# RL6845_IP_SVD register map
Vendor: Realtek
Registers are 32-bit, read-write, reset 0x0 unless marked. A register's access mark holds for its fields unless they carry their own. Offsets are from the block's base; [hi:lo] are bit positions.

## KSCAN_REG
Base 0x41013000
0x00 KS_CLK_DIV — clock division register
  [11:0] ks_clk_div — scan clock = bus clock/(keyscan_clk_div+1)
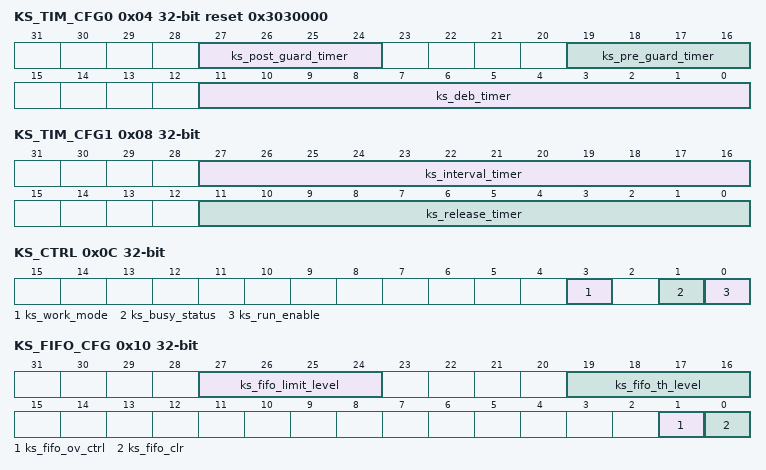
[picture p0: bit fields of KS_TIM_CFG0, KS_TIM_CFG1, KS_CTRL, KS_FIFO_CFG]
0x04 KS_TIM_CFG0 reset 0x3030000 — Key-Scan configure register 0
  [27:24] ks_post_guard_timer — Post guard time for key column, post guard time = scan_clk * reg_col_gt_post_sel
  [19:16] ks_pre_guard_timer — Pre guard time for key column, pre guard time = scan_clk * reg_col_gt_pre_sel
  [11:0] ks_deb_timer — Debounce counter n*scan_clk
0x08 KS_TIM_CFG1 — Key-Scan configure register 1
  [27:16] ks_interval_timer — Scan interval counter n*scan_clk
  [11:0] ks_release_timer — Release detect counter n*scan_clk
0x0C KS_CTRL access per field — Key-Scan control register
  [3] ks_work_mode rw — Work mode *0x1: Event Trigger Mode *0x0: Regular Scan Mode
  [1] ks_busy_status ro — FSM busy status
  [0] ks_run_enable rw — Enable internal Key-Scan scan clock. The Key-Scan clock enable must be after Key-Scan configuration is done. *0x1: Key-Scan clock enabled (HW FSM starts to run). *0x0: Key-Scan clock disabled (HW FSM stops).
0x10 KS_FIFO_CFG access per field — FIFO configuration register
  [27:24] ks_fifo_limit_level rw — Limit the max allowable key number be pressed at a time 0x0: no limit 0x1: only one scan data is allowable in each key scan ... 0x6: Max 6 scan data is allowable in each key scan 0x7 ~ 0xf: DO NOT USE
  [19:16] ks_fifo_th_level rw — FIFO threshold setup
  [1] ks_fifo_ov_ctrl rw — FIFO overflow control 0x0: rejects the new scan data when FIFO is full 0x1: discard the oldest scan data when FIFO is full
  [0] ks_fifo_clr wo — Write 1to clear FIFO data
0x14 KS_COL_CFG — column selection register
  [7:0] ks_col_sel — The control register to define which column is used. *0x0: No key column selected *0x1: Key column 0 selected *0x2: Key column 1 selected *0x3: Key column 0 and column 1 selected *0x4: Key column 2 selected *...
0x18 KS_ROW_CFG — row selection register
  [7:0] ks_row_sel — The control register to define which row is used. *0x0: No key row selected *0x1: Key row 0 selected *0x2: Key row 1 selected *0x3: Key row 0 and row 1 selected *0x4: Key row 2 selected *...
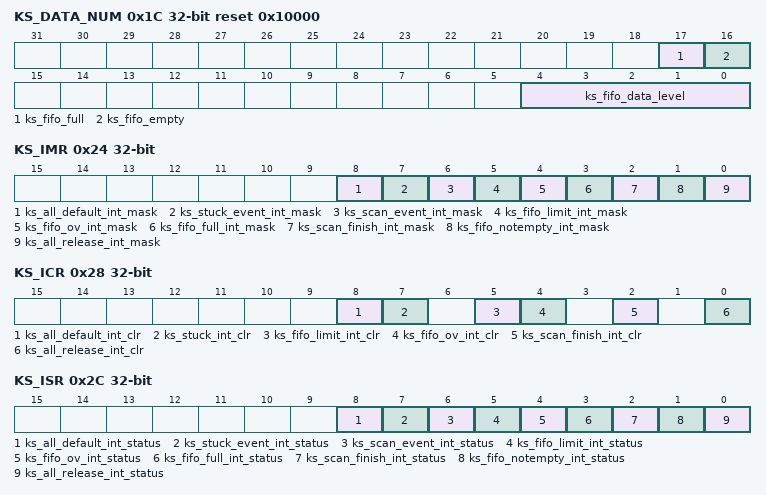
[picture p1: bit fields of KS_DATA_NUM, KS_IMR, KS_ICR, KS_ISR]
0x1C KS_DATA_NUM ro reset 0x10000 — FIFO status
  [17] ks_fifo_full — FIFO full status
  [16] ks_fifo_empty — FIFO empty status
  [4:0] ks_fifo_data_level — Number of entry in FIFO
0x20 KS_DATA ro — Key-Scan data register
  [11:0] ks_data — When reading this register, these bits return the value in the Event FIFO. *Bit[11:8]: press or release event **0x0: release event **0x1: press event *Bit[7:4]: row index *Bit[3:0]: column index
0x24 KS_IMR — interrupt mask register
  [8] ks_all_default_int_mask — 0x0: Mask all default interrupt
  [7] ks_stuck_event_int_mask — 0x0: Mask stuck event interrupt
  [6] ks_scan_event_int_mask — 0x0: Mask scan event interrupt
  [5] ks_fifo_limit_int_mask — 0x0: Mask FIFO limit interrupt
  [4] ks_fifo_ov_int_mask — 0x0: Mask FIFO overflow interrupt
  [3] ks_fifo_full_int_mask — 0x0: Mask FIFO full interrupt
  [2] ks_scan_finish_int_mask — 0x0: Mask scan finish interrupt
  [1] ks_fifo_notempty_int_mask — 0x0: Mask FIFO nonempty interrupt
  [0] ks_all_release_int_mask — 0x0: Mask All Release interrupt
0x28 KS_ICR wo — interrupt clear register
  [8] ks_all_default_int_clr — Clear All Default interrupt flag Write '1' to clear
  [7] ks_stuck_int_clr — Clear Stuck interrupt flag Write '1' to clear
  [5] ks_fifo_limit_int_clr — Clear FIFO limit interrupt flag Write '1' to clear
  [4] ks_fifo_ov_int_clr — Clear FIFO overflow interrupt flag Write '1' to clear
  [2] ks_scan_finish_int_clr — Clear scan finish interrupt flag Write '1' to clear
  [0] ks_all_release_int_clr — Clear all release interrupt flag Write '1' to clear
0x2C KS_ISR ro — interrupt status register
  [8] ks_all_default_int_status — Masked All Default interrupt status, means row status equal to ks_row_default_status
  [7] ks_stuck_event_int_status — Masked Stuck event interrupt status
  [6] ks_scan_event_int_status — Masked Scan event interrupt status
  [5] ks_fifo_limit_int_status — Masked FIFO limit interrupt status
  [4] ks_fifo_ov_int_status — Masked FIFO overflow interrupt status
  [3] ks_fifo_full_int_status — Masked FIFO full interrupt status
  [2] ks_scan_finish_int_status — Masked Scan finish interrupt status
  [1] ks_fifo_notempty_int_status — Masked FIFO nonempty interrupt status
  [0] ks_all_release_int_status — Masked All release interrupt status
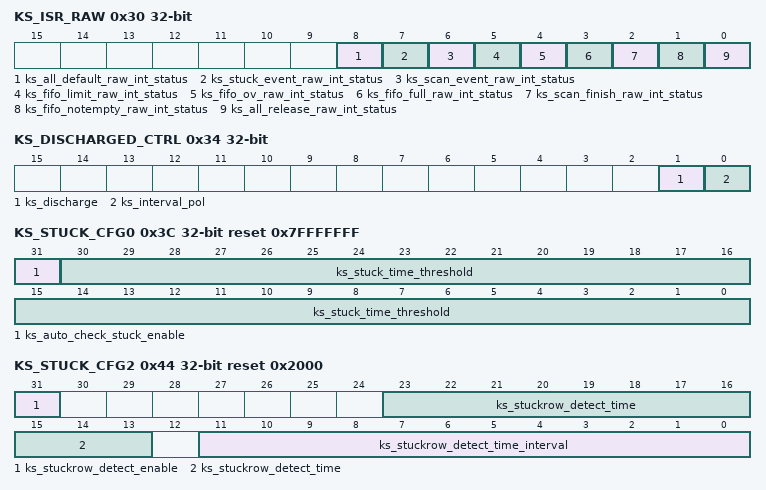
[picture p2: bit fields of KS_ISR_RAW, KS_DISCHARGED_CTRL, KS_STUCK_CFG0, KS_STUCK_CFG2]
0x30 KS_ISR_RAW ro — raw interrupt flag register
  [8] ks_all_default_raw_int_status — All default interrupt, means row status equal to ks_row_default_status
  [7] ks_stuck_event_raw_int_status — Key stuck event raw interrupt
  [6] ks_scan_event_raw_int_status — Scan event raw interrupt, auto clear when the item is read
  [5] ks_fifo_limit_raw_int_status — FIFO limit raw interrupt
  [4] ks_fifo_ov_raw_int_status — FIFO overflow raw interrupt
  [3] ks_fifo_full_raw_int_status — FIFO full raw interrupt
  [2] ks_scan_finish_raw_int_status — Scan finish raw interrupt
  [1] ks_fifo_notempty_raw_int_status — FIFO nonempty raw interrupt Auto clear when FIFO is empty
  [0] ks_all_release_raw_int_status — All Release raw interrupt
0x34 KS_DISCHARGED_CTRL — keyboard discharged register
  [1] ks_discharge — 1: The keyboard is discharged before scan.
  [0] ks_interval_pol — 1: The keyboard is discharged at interval (FSM!=scan idle allrelease).
0x3C KS_STUCK_CFG0 reset 0x7FFFFFFF — Key-Scan Stuck Configuration Register
  [31] ks_auto_check_stuck_enable — Enable auto check stuck or not *0x1: Key-Scan auto chek stuck enabled. *0x0: Key-Scan auto check stuck disabled.
  [30:0] ks_stuck_time_threshold — When the threshold is exceeded, it is considered to be stuck event or release stuck key, this counter is in scan clk.
0x40 KS_STUCK_CFG1 reset 0xFF — Key-Scan Stuck Configuration Register 1
  [7:0] ks_row_default_status — Keyboard row default status: *0b11111111: No key row is stucked *0b11111110: Key row 0 is stucked *0b11111101: Key row 1 is stucked *0b11111100: Key row 0 and column 1 are stucked *0b11111011: Key row 2 is stucked* ...
0x44 KS_STUCK_CFG2 reset 0x2000 — Key-Scan Stuck Configuration Register 2
  [31] ks_stuckrow_detect_enable — Enable stuckrow detect function, and row gpio will be "no pull" state in ks_stuckrow_detect_time_interval
  [23:13] ks_stuckrow_detect_time — Key-Scan stuckrow detect timer, this counter is in clk_131k
  [11:0] ks_stuckrow_detect_time_interval — Key-Scan stuckrow detect interval timer, this counter is in clk_131k
0x48 KS_STUCK_KEY_STATUS1 ro — Key-Scan Status Register 1
  [31:0] ks_key_status1 — Each bit means the corresponding key's stuck state *0x1: key stucked *0x0: key unstucked Corresponding: key_status1[7:0] - row0[7:0] key_status1[15:8] - row1[7:0] key_status1[13:16] - row2[7:0] key_status1[31:24] - row3[7:0]
0x4C KS_STUCK_KEY_STATUS2 ro — Key-Scan Status Register 2
  [31:0] ks_key_status2 — Each bit means the corresponding key's stuck state *0x1: key stucked *0x0: key unstucked Corresponding: key_status2[7:0] - row4[7:0] key_status2[15:8] - row5[7:0] key_status2[13:16] - row6[7:0] key_status2[31:24] - row7[7:0]
0x50 KS_STUCK_KEY_ROW_STATUS1 ro — Key-Scan Row Status Register 1
  [7:0] ks_row_status — Each bit means the corresponding key row's stuck state *0x1: row stucked *0x0: row unstucked Corresponding: row_status[7:0] - row[7:0]
0x58 KS_DUMMY — Key-Scan Dummy Register
  [15:0] dummy — Reserved for HW
